# msp430fr5739 register map
Registers from a debugger description file.
Registers are 16-bit, access not given, no defined reset value unless marked. A register's access mark holds for its fields unless they carry their own. Addresses are absolute; registers are grouped by the start of their names; lines under a group give offsets from that group; [hi:lo] are bit positions; {n}, {i} and the like mark numbered series; 'fields as' and 'values as' point back to an identical list; <NAME> marks a mode.

## UCA0IE
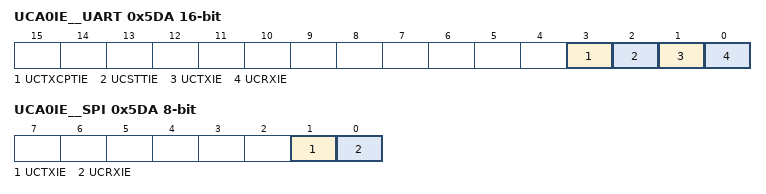
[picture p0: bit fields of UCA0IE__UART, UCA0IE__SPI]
0x5DA UCA0IE__UART
  [3] UCTXCPTIE, [2] UCSTTIE, [1] UCTXIE, [0] UCRXIE
0x5DA UCA0IE__SPI 8-bit
  [1] UCTXIE, [0] UCRXIE

## UCA0IFG
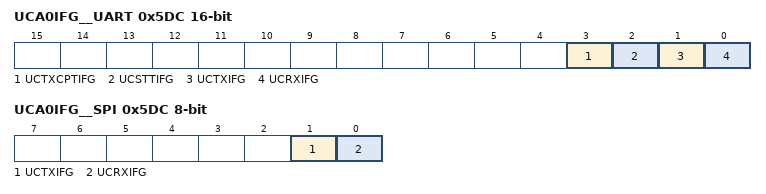
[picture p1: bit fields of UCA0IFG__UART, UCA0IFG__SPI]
0x5DC UCA0IFG__UART
  [3] UCTXCPTIFG, [2] UCSTTIFG, [1] UCTXIFG, [0] UCRXIFG
0x5DC UCA0IFG__SPI 8-bit
  [1] UCTXIFG, [0] UCRXIFG

## UCB0STATW
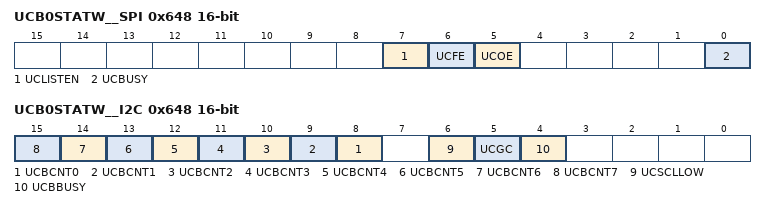
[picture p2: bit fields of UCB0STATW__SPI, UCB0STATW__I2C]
0x648 UCB0STATW__SPI
  [7] UCLISTEN, [6] UCFE, [5] UCOE, [0] UCBUSY
0x648 UCB0STATW__I2C
  [n+8] UCBCNT{n} (n=0..7), [6] UCSCLLOW, [5] UCGC, [4] UCBBUSY

## UCB0IE
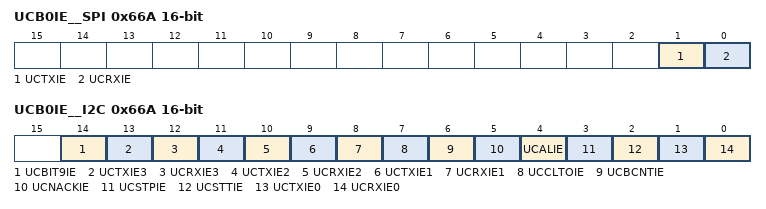
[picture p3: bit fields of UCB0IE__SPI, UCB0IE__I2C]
0x66A UCB0IE__SPI
  [1] UCTXIE, [0] UCRXIE
0x66A UCB0IE__I2C
  [14] UCBIT9IE, [13] UCTXIE3, [12] UCRXIE3, [11] UCTXIE2, [10] UCRXIE2, [9] UCTXIE1, [8] UCRXIE1, [7] UCCLTOIE, [6] UCBCNTIE, [5] UCNACKIE, [4] UCALIE, [3] UCSTPIE, [2] UCSTTIE, [1] UCTXIE0, [0] UCRXIE0

## UCB0IFG
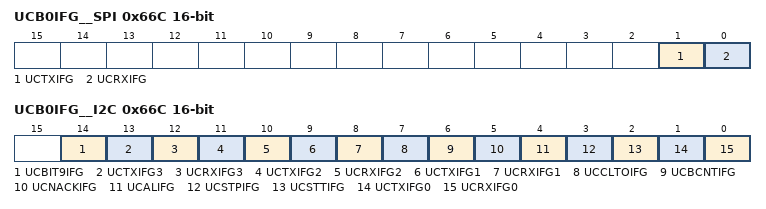
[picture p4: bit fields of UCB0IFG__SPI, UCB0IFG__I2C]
0x66C UCB0IFG__SPI
  [1] UCTXIFG, [0] UCRXIFG
0x66C UCB0IFG__I2C
  [14] UCBIT9IFG, [13] UCTXIFG3, [12] UCRXIFG3, [11] UCTXIFG2, [10] UCRXIFG2, [9] UCTXIFG1, [8] UCRXIFG1, [7] UCCLTOIFG, [6] UCBCNTIFG, [5] UCNACKIFG, [4] UCALIFG, [3] UCSTPIFG, [2] UCSTTIFG, [1] UCTXIFG0, [0] UCRXIFG0

## UCA1IE
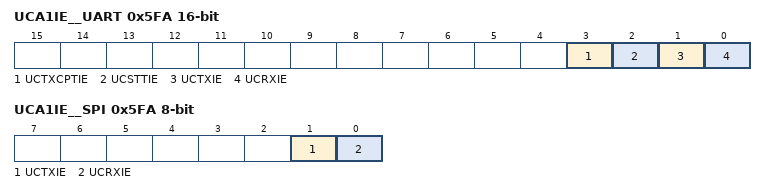
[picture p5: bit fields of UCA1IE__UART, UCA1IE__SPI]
0x5FA UCA1IE__UART
  [3] UCTXCPTIE, [2] UCSTTIE, [1] UCTXIE, [0] UCRXIE
0x5FA UCA1IE__SPI 8-bit
  [1] UCTXIE, [0] UCRXIE

## UCA1IFG
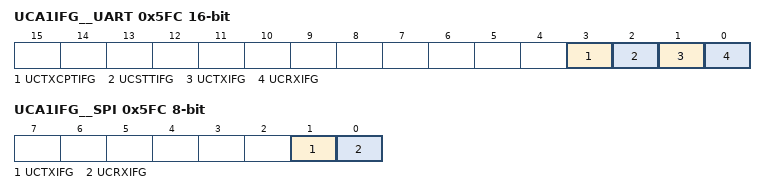
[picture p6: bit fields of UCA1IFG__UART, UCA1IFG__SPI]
0x5FC UCA1IFG__UART
  [3] UCTXCPTIFG, [2] UCSTTIFG, [1] UCTXIFG, [0] UCRXIFG
0x5FC UCA1IFG__SPI 8-bit
  [1] UCTXIFG, [0] UCRXIFG

## Notices in the file
Copyright 1996-2003 Texas Instruments. All rights reserved.
